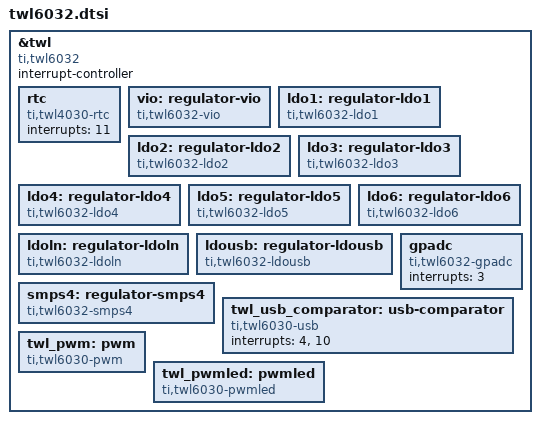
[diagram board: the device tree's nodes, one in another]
// SPDX-License-Identifier: GPL-2.0-only
/*
 * Integrated Power Management Chip
 * https://www.ti.com/lit/ds/symlink/twl6032.pdf
 */

&twl {
	compatible = "ti,twl6032";
	interrupt-controller;
	#interrupt-cells = <1>;

	rtc {
		compatible = "ti,twl4030-rtc";
		interrupts = <11>;
	};

	vio: regulator-vio {
		compatible = "ti,twl6032-vio";
	};

	ldo1: regulator-ldo1 {
		compatible = "ti,twl6032-ldo1";
	};

	ldo2: regulator-ldo2 {
		compatible = "ti,twl6032-ldo2";
	};

	ldo3: regulator-ldo3 {
		compatible = "ti,twl6032-ldo3";
	};

	ldo4: regulator-ldo4 {
		compatible = "ti,twl6032-ldo4";
	};

	ldo5: regulator-ldo5 {
		compatible = "ti,twl6032-ldo5";
	};

	ldo6: regulator-ldo6 {
		compatible = "ti,twl6032-ldo6";
	};

	ldoln: regulator-ldoln {
		compatible = "ti,twl6032-ldoln";
	};

	ldousb: regulator-ldousb {
		compatible = "ti,twl6032-ldousb";
	};

	smps4: regulator-smps4 {
		compatible = "ti,twl6032-smps4";
	};

	gpadc: gpadc {
		compatible = "ti,twl6032-gpadc";
		interrupts = <3>;
		#io-channel-cells = <1>;
	};

	twl_usb_comparator: usb-comparator {
		compatible = "ti,twl6030-usb";
		interrupts = <4>, <10>;
	};

	twl_pwm: pwm {
		compatible = "ti,twl6030-pwm";
		#pwm-cells = <2>;
	};

	twl_pwmled: pwmled {
		compatible = "ti,twl6030-pwmled";
		#pwm-cells = <2>;
	};
};
